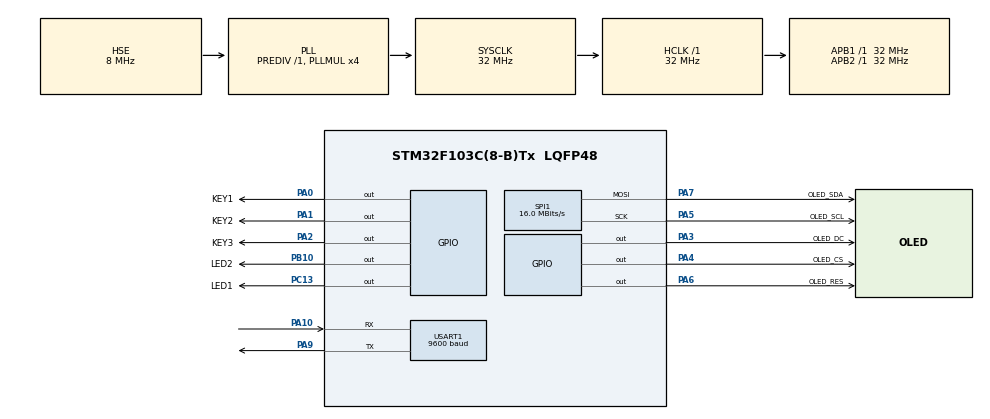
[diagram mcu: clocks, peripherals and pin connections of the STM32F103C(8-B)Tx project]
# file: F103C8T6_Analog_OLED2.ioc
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Mcu.Family=STM32F1
Mcu.Name=STM32F103C(8-B)Tx
Mcu.Package=LQFP48
NVIC.PriorityGroup=NVIC_PRIORITYGROUP_4
NVIC.TIM1_UP_IRQn=true\:0\:0\:false\:false\:true\:true\:true
NVIC.USART1_IRQn=true\:0\:0\:false\:false\:true\:true\:true
PA0-WKUP.GPIO_Label=KEY1
PA0-WKUP.GPIO_PuPd=GPIO_PULLUP
PA0-WKUP.GPIO_Speed=GPIO_SPEED_FREQ_HIGH
PA0-WKUP.PinState=GPIO_PIN_SET
PA0-WKUP.Signal=GPIO_Output
PA1.GPIO_Label=KEY2
PA1.GPIO_PuPd=GPIO_PULLUP
PA1.GPIO_Speed=GPIO_SPEED_FREQ_HIGH
PA1.PinState=GPIO_PIN_SET
PA1.Signal=GPIO_Output
PA10.Mode=Asynchronous
PA10.Signal=USART1_RX
PA13.Mode=Serial_Wire
PA13.Signal=SYS_JTMS-SWDIO
PA14.Mode=Serial_Wire
PA14.Signal=SYS_JTCK-SWCLK
PA2.GPIO_Label=KEY3
PA2.GPIO_PuPd=GPIO_PULLUP
PA2.GPIO_Speed=GPIO_SPEED_FREQ_HIGH
PA2.PinState=GPIO_PIN_SET
PA2.Signal=GPIO_Output
PA3.GPIO_Label=OLED_DC
PA3.GPIO_PuPd=GPIO_PULLUP
PA3.GPIO_Speed=GPIO_SPEED_FREQ_HIGH
PA3.PinState=GPIO_PIN_SET
PA3.Signal=GPIO_Output
PA4.GPIO_Label=OLED_CS
PA4.GPIO_ModeDefaultOutputPP=GPIO_MODE_OUTPUT_PP
PA4.GPIO_PuPd=GPIO_PULLUP
PA4.GPIO_Speed=GPIO_SPEED_FREQ_HIGH
PA4.PinState=GPIO_PIN_SET
PA4.Signal=GPIO_Output
PA5.GPIO_Label=OLED_SCL
PA5.Mode=TX_Only_Simplex_Unidirect_Master
PA5.Signal=SPI1_SCK
PA6.GPIO_Label=OLED_RES
PA6.GPIO_ModeDefaultOutputPP=GPIO_MODE_OUTPUT_PP
PA6.GPIO_PuPd=GPIO_PULLUP
PA6.GPIO_Speed=GPIO_SPEED_FREQ_HIGH
PA6.PinState=GPIO_PIN_SET
PA6.Signal=GPIO_Output
PA7.GPIO_Label=OLED_SDA
PA7.Mode=TX_Only_Simplex_Unidirect_Master
PA7.Signal=SPI1_MOSI
PA9.Mode=Asynchronous
PA9.Signal=USART1_TX
PB10.GPIO_Label=LED2
PB10.GPIO_PuPd=GPIO_PULLDOWN
PB10.GPIO_Speed=GPIO_SPEED_FREQ_HIGH
PB10.PinState=GPIO_PIN_RESET
PB10.Signal=GPIO_Output
PC13-TAMPER-RTC.GPIO_Label=LED1
PC13-TAMPER-RTC.GPIO_ModeDefaultOutputPP=GPIO_MODE_OUTPUT_PP
PC13-TAMPER-RTC.GPIO_PuPd=GPIO_PULLUP
PC13-TAMPER-RTC.GPIO_Speed=GPIO_SPEED_FREQ_HIGH
PC13-TAMPER-RTC.PinState=GPIO_PIN_SET
PC13-TAMPER-RTC.Signal=GPIO_Output
PC14-OSC32_IN.Mode=LSE-External-Oscillator
PC14-OSC32_IN.Signal=RCC_OSC32_IN
PC15-OSC32_OUT.Mode=LSE-External-Oscillator
PC15-OSC32_OUT.Signal=RCC_OSC32_OUT
PD0-OSC_IN.Mode=HSE-External-Oscillator
PD0-OSC_IN.Signal=RCC_OSC_IN
PD1-OSC_OUT.Mode=HSE-External-Oscillator
PD1-OSC_OUT.Signal=RCC_OSC_OUT
ProjectManager.HeapSize=0x200
ProjectManager.StackSize=0x400
ProjectManager.TargetToolchain=STM32CubeIDE
RCC.ADCPresc=RCC_ADCPCLK2_DIV4
RCC.AHBFreq_Value=32000000
RCC.APB1Freq_Value=32000000
RCC.APB1TimFreq_Value=32000000
RCC.APB2Freq_Value=32000000
RCC.APB2TimFreq_Value=32000000
RCC.HCLKFreq_Value=32000000
RCC.PLLMUL=RCC_PLL_MUL4
RCC.PLLSourceVirtual=RCC_PLLSOURCE_HSE
RCC.SYSCLKFreq_VALUE=32000000
RCC.SYSCLKSource=RCC_SYSCLKSOURCE_PLLCLK
RCC.USBFreq_Value=32000000
SPI1.BaudRatePrescaler=SPI_BAUDRATEPRESCALER_2
SPI1.CalculateBaudRate=16.0 MBits/s
SPI1.Direction=SPI_DIRECTION_2LINES
SPI1.Mode=SPI_MODE_MASTER
SPI1.VirtualType=VM_MASTER
TIM1.AutoReloadPreload=TIM_AUTORELOAD_PRELOAD_ENABLE
TIM1.Period=1999
TIM1.Prescaler=999
USART1.BaudRate=9600
USART1.VirtualMode=VM_ASYNC
VP_TIM1_VS_ClockSourceINT.Mode=Internal
board=custom

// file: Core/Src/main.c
/* USER CODE BEGIN Header */
/**
  ******************************************************************************
  * @file           : main.c
  * @brief          : Main program body
  ******************************************************************************
  * @attention
  *
  * Copyright (c) 2022 STMicroelectronics.
  * All rights reserved.
  *
  * This software is licensed under terms that can be found in the LICENSE file
  * in the root directory of this software component.
  * If no LICENSE file comes with this software, it is provided AS-IS.
  *
  ******************************************************************************
  */
/* USER CODE END Header */
#include "main.h"
#include "spi.h"
#include "tim.h"
#include "usart.h"
#include "gpio.h"

/* USER CODE BEGIN Includes */
#include "stdio.h"
#include "OLED.h"
/* USER CODE END Includes */

void SystemClock_Config(void);

int main(void)
{

  /* MCU Configuration--------------------------------------------------------*/

  /* Reset of all peripherals, Initializes the Flash interface and the Systick. */
  HAL_Init();

  /* Configure the system clock */
  SystemClock_Config();

  /* Initialize all configured peripherals */
  MX_GPIO_Init();
  MX_SPI1_Init();
  MX_USART1_UART_Init();
  MX_TIM1_Init();
  /* USER CODE BEGIN 2 */
  OLED_init();
  OLED_full();
  OLED_clear();

  /* USER CODE END 2 */

  /* Infinite loop */
  /* USER CODE BEGIN WHILE */
  while (1)
  {
	  OLED_full();

    /* USER CODE END WHILE */

  }
}

void SystemClock_Config(void)
{
  RCC_OscInitTypeDef RCC_OscInitStruct = {0};
  RCC_ClkInitTypeDef RCC_ClkInitStruct = {0};

  /** Initializes the RCC Oscillators according to the specified parameters
  * in the RCC_OscInitTypeDef structure.
  */
  RCC_OscInitStruct.OscillatorType = RCC_OSCILLATORTYPE_HSE;
  RCC_OscInitStruct.HSEState = RCC_HSE_ON;
  RCC_OscInitStruct.HSEPredivValue = RCC_HSE_PREDIV_DIV1;
  RCC_OscInitStruct.HSIState = RCC_HSI_ON;
  RCC_OscInitStruct.PLL.PLLState = RCC_PLL_ON;
  RCC_OscInitStruct.PLL.PLLSource = RCC_PLLSOURCE_HSE;
  RCC_OscInitStruct.PLL.PLLMUL = RCC_PLL_MUL4;
  if (HAL_RCC_OscConfig(&RCC_OscInitStruct) != HAL_OK)
  {
    Error_Handler();
  }
  /** Initializes the CPU, AHB and APB buses clocks
  */
  RCC_ClkInitStruct.ClockType = RCC_CLOCKTYPE_HCLK|RCC_CLOCKTYPE_SYSCLK
                              |RCC_CLOCKTYPE_PCLK1|RCC_CLOCKTYPE_PCLK2;
  RCC_ClkInitStruct.SYSCLKSource = RCC_SYSCLKSOURCE_PLLCLK;
  RCC_ClkInitStruct.AHBCLKDivider = RCC_SYSCLK_DIV1;
  RCC_ClkInitStruct.APB1CLKDivider = RCC_HCLK_DIV1;
  RCC_ClkInitStruct.APB2CLKDivider = RCC_HCLK_DIV1;

  if (HAL_RCC_ClockConfig(&RCC_ClkInitStruct, FLASH_LATENCY_1) != HAL_OK)
  {
    Error_Handler();
  }
}

void Error_Handler(void)
{
  __disable_irq();
  while (1)
  {
  }
}
